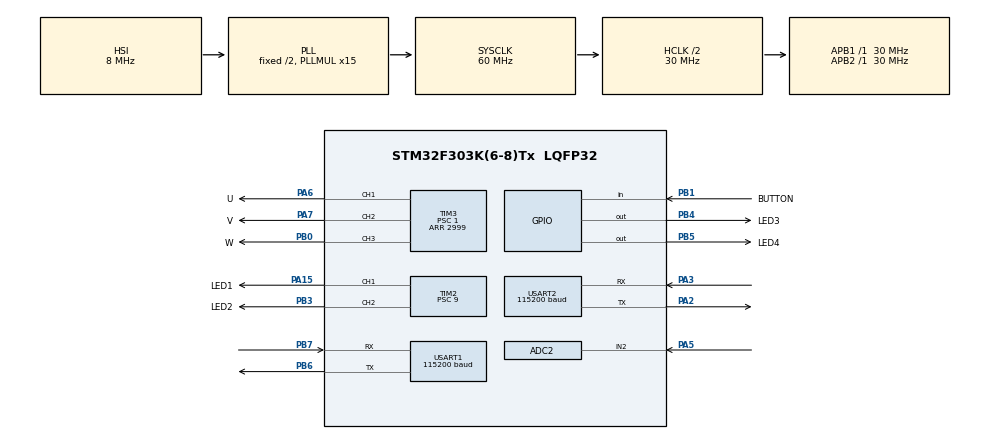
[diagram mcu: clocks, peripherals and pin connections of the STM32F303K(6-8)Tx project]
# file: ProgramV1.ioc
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ADC2.Channel-1\#ChannelRegularConversion=ADC_CHANNEL_2
ADC2.ClockPrescaler=ADC_CLOCK_ASYNC_DIV1
ADC2.ContinuousConvMode=ENABLE
ADC2.DMAContinuousRequests=ENABLE
ADC2.NbrOfConversion=1
ADC2.NbrOfConversionFlag=1
ADC2.Offset-1\#ChannelRegularConversion=0
ADC2.OffsetNumber-1\#ChannelRegularConversion=ADC_OFFSET_NONE
ADC2.Rank-1\#ChannelRegularConversion=1
ADC2.SamplingTime-1\#ChannelRegularConversion=ADC_SAMPLETIME_1CYCLE_5
ADC2.SamplingTimeOPAMP-1\#ChannelRegularConversion=ADC_SAMPLETIME_4CYCLES_5
ADC2.SubFamily=STM32F303x8
Dma.ADC2.0.Direction=DMA_PERIPH_TO_MEMORY
Dma.ADC2.0.Instance=DMA1_Channel2
Dma.ADC2.0.MemDataAlignment=DMA_MDATAALIGN_HALFWORD
Dma.ADC2.0.MemInc=DMA_MINC_ENABLE
Dma.ADC2.0.Mode=DMA_CIRCULAR
Dma.ADC2.0.PeriphDataAlignment=DMA_PDATAALIGN_HALFWORD
Dma.ADC2.0.PeriphInc=DMA_PINC_DISABLE
Dma.ADC2.0.Priority=DMA_PRIORITY_LOW
Dma.Request0=ADC2
Mcu.Family=STM32F3
Mcu.Name=STM32F303K(6-8)Tx
Mcu.Package=LQFP32
NVIC.ADC1_2_IRQn=true\:0\:0\:false\:false\:true\:true\:true\:true
NVIC.DMA1_Channel2_IRQn=true\:0\:0\:false\:false\:true\:false\:true\:true
NVIC.PriorityGroup=NVIC_PRIORITYGROUP_4
PA13.Signal=SYS_JTMS-SWDIO
PA14.Signal=SYS_JTCK-SWCLK
PA15.GPIO_Label=LED1
PA15.Signal=S_TIM2_CH1_ETR
PA2.Mode=Asynchronous
PA2.Signal=USART2_TX
PA3.Mode=Asynchronous
PA3.Signal=USART2_RX
PA5.Mode=IN2-Single-Ended
PA5.Signal=ADC2_IN2
PA6.GPIO_Label=U
PA6.Signal=S_TIM3_CH1
PA7.GPIO_Label=V
PA7.Signal=S_TIM3_CH2
PB0.GPIO_Label=W
PB0.Signal=S_TIM3_CH3
PB1.GPIO_Label=BUTTON
PB1.Signal=GPIO_Input
PB3.GPIO_Label=LED2
PB3.Signal=S_TIM2_CH2
PB4.GPIO_Label=LED3
PB4.Signal=GPIO_Output
PB5.GPIO_Label=LED4
PB5.Signal=GPIO_Output
PB6.Mode=Asynchronous
PB6.Signal=USART1_TX
PB7.Mode=Asynchronous
PB7.Signal=USART1_RX
PF0\ /\ OSC_IN.Mode=HSE-External-Oscillator
PF0\ /\ OSC_IN.Signal=RCC_OSC_IN
PF1\ /\ OSC_OUT.Mode=HSE-External-Oscillator
PF1\ /\ OSC_OUT.Signal=RCC_OSC_OUT
ProjectManager.HeapSize=0x200
ProjectManager.StackSize=0x400
ProjectManager.TargetToolchain=Makefile
RCC.AHBCLKDivider=RCC_SYSCLK_DIV2
RCC.AHBFreq_Value=30000000
RCC.APB1Freq_Value=30000000
RCC.APB1TimFreq_Value=30000000
RCC.APB2Freq_Value=30000000
RCC.APB2TimFreq_Value=30000000
RCC.CortexFreq_Value=30000000
RCC.HCLKFreq_Value=30000000
RCC.HSE_VALUE=16000000
RCC.HSI_VALUE=8000000
RCC.PLLMUL=RCC_PLL_MUL15
RCC.SYSCLKFreq_VALUE=60000000
RCC.SYSCLKSourceVirtual=RCC_SYSCLKSOURCE_PLLCLK
SH.S_TIM2_CH1_ETR.0=TIM2_CH1,PWM Generation1 CH1
SH.S_TIM2_CH2.0=TIM2_CH2,PWM Generation2 CH2
SH.S_TIM3_CH1.0=TIM3_CH1,PWM Generation1 CH1
SH.S_TIM3_CH2.0=TIM3_CH2,PWM Generation2 CH2
SH.S_TIM3_CH3.0=TIM3_CH3,PWM Generation3 CH3
TIM2.Channel-PWM\ Generation1\ CH1=TIM_CHANNEL_1
TIM2.Channel-PWM\ Generation2\ CH2=TIM_CHANNEL_2
TIM2.Period=299
TIM2.Prescaler=9
TIM3.AutoReloadPreload=TIM_AUTORELOAD_PRELOAD_ENABLE
TIM3.Channel-PWM\ Generation1\ CH1=TIM_CHANNEL_1
TIM3.Channel-PWM\ Generation2\ CH2=TIM_CHANNEL_2
TIM3.Channel-PWM\ Generation3\ CH3=TIM_CHANNEL_3
TIM3.OCFastMode_PWM-PWM\ Generation1\ CH1=TIM_OCFAST_DISABLE
TIM3.OCFastMode_PWM-PWM\ Generation2\ CH2=TIM_OCFAST_DISABLE
TIM3.OCFastMode_PWM-PWM\ Generation3\ CH3=TIM_OCFAST_DISABLE
TIM3.Period=2999
TIM3.Prescaler=1
USART1.BaudRate=115200
USART1.VirtualMode-Asynchronous=VM_ASYNC
USART2.BaudRate=115200
USART2.VirtualMode-Asynchronous=VM_ASYNC
board=custom

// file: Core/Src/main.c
/* USER CODE BEGIN Header */
/**
 ******************************************************************************
 * @file           : main.c
 * @brief          : Main program body
 ******************************************************************************
 * @attention
 *
 * Copyright (c) 2025 STMicroelectronics.
 * All rights reserved.
 *
 * This software is licensed under terms that can be found in the LICENSE file
 * in the root directory of this software component.
 * If no LICENSE file comes with this software, it is provided AS-IS.
 *
 ******************************************************************************
 */
/* USER CODE END Header */
#include "main.h"
#include "adc.h"
#include "dma.h"
#include "tim.h"
#include "usart.h"
#include "gpio.h"

/* USER CODE BEGIN Includes */
#include "app.h"
/* USER CODE END Includes */

void SystemClock_Config(void);

int main(void)
{

  /* MCU Configuration--------------------------------------------------------*/

  /* Reset of all peripherals, Initializes the Flash interface and the Systick. */
  HAL_Init();

  /* Configure the system clock */
  SystemClock_Config();

  /* Initialize all configured peripherals */
  MX_GPIO_Init();
  MX_DMA_Init();
  MX_USART1_UART_Init();
  MX_USART2_UART_Init();
  MX_TIM3_Init();
  MX_TIM2_Init();
  MX_ADC2_Init();

  /* Infinite loop */
  /* USER CODE BEGIN WHILE */
      setup();     // Call the setup function from app.c
      main_app();  // Call the main application function from app.c
      while (1) {
    /* USER CODE END WHILE */

      }
}

void SystemClock_Config(void)
{
  RCC_OscInitTypeDef RCC_OscInitStruct = {0};
  RCC_ClkInitTypeDef RCC_ClkInitStruct = {0};
  RCC_PeriphCLKInitTypeDef PeriphClkInit = {0};

  /** Initializes the RCC Oscillators according to the specified parameters
  * in the RCC_OscInitTypeDef structure.
  */
  RCC_OscInitStruct.OscillatorType = RCC_OSCILLATORTYPE_HSI;
  RCC_OscInitStruct.HSIState = RCC_HSI_ON;
  RCC_OscInitStruct.HSICalibrationValue = RCC_HSICALIBRATION_DEFAULT;
  RCC_OscInitStruct.PLL.PLLState = RCC_PLL_ON;
  RCC_OscInitStruct.PLL.PLLSource = RCC_PLLSOURCE_HSI;
  RCC_OscInitStruct.PLL.PLLMUL = RCC_PLL_MUL15;
  if (HAL_RCC_OscConfig(&RCC_OscInitStruct) != HAL_OK)
  {
    Error_Handler();
  }

  /** Initializes the CPU, AHB and APB buses clocks
  */
  RCC_ClkInitStruct.ClockType = RCC_CLOCKTYPE_HCLK|RCC_CLOCKTYPE_SYSCLK
                              |RCC_CLOCKTYPE_PCLK1|RCC_CLOCKTYPE_PCLK2;
  RCC_ClkInitStruct.SYSCLKSource = RCC_SYSCLKSOURCE_PLLCLK;
  RCC_ClkInitStruct.AHBCLKDivider = RCC_SYSCLK_DIV2;
  RCC_ClkInitStruct.APB1CLKDivider = RCC_HCLK_DIV1;
  RCC_ClkInitStruct.APB2CLKDivider = RCC_HCLK_DIV1;

  if (HAL_RCC_ClockConfig(&RCC_ClkInitStruct, FLASH_LATENCY_1) != HAL_OK)
  {
    Error_Handler();
  }
  PeriphClkInit.PeriphClockSelection = RCC_PERIPHCLK_USART1|RCC_PERIPHCLK_ADC12;
  PeriphClkInit.Usart1ClockSelection = RCC_USART1CLKSOURCE_PCLK1;
  PeriphClkInit.Adc12ClockSelection = RCC_ADC12PLLCLK_DIV1;
  if (HAL_RCCEx_PeriphCLKConfig(&PeriphClkInit) != HAL_OK)
  {
    Error_Handler();
  }
}

void Error_Handler(void)
{
      __disable_irq();
      while (1) {
      }
}
